# psc3 register map
Vendor: Infineon Technologies; Series: PSC3; File version: 1.0
CPU: CM33 r0p1, little endian, MPU, FPU, VTOR, 3 interrupt priority bits
Registers are 32-bit, read-write, reset 0x0 unless marked. A register's access mark holds for its fields unless they carry their own. Offsets are from the block's base; [hi:lo] are bit positions; lines under a group give offsets from that group; {n}, {i} and the like mark numbered series.

## MXCORDIC_1_0
Base 0x42240000
0x00 CTL
  [31] ENABLED — Enables/Disables IP
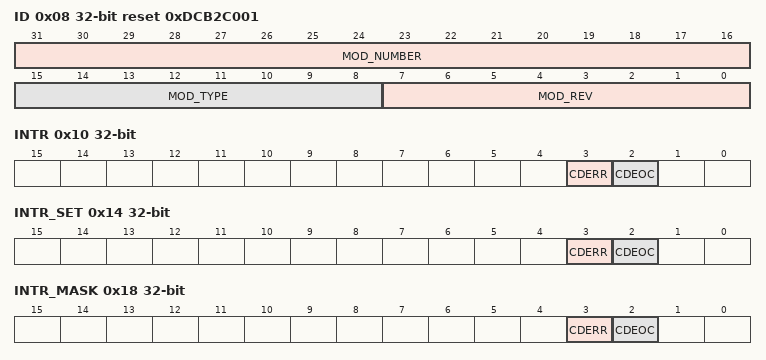
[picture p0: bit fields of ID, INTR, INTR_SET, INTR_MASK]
0x08 ID ro reset 0xDCB2C001 — Module Identification Register
  [31:16] MOD_NUMBER — Module Number Value - MOD_NUMBER
  [15:8] MOD_TYPE — Module Type - MOD_TYPE
  [7:0] MOD_REV — Module Revision Number - MOD_REV
0x10 INTR — Interrupt Cause Register
  [3] CDERR — CORDIC Error Event Flag - CDERR
  [2] CDEOC — CORDIC End of Calculation Event Flag - CDEOC
0x14 INTR_SET — Interrupt Set Register
  [3] CDERR — CORDIC Error Event Flag Set - CDERR
  [2] CDEOC — CORDIC Event Flag Set - CDEOC
0x18 INTR_MASK — Interrupt Mask Register
  [3] CDERR — CORDIC Error Interrupt Mask - CDERR
  [2] CDEOC — CORDIC End of Calculation Interrupt Mask- CDEOC
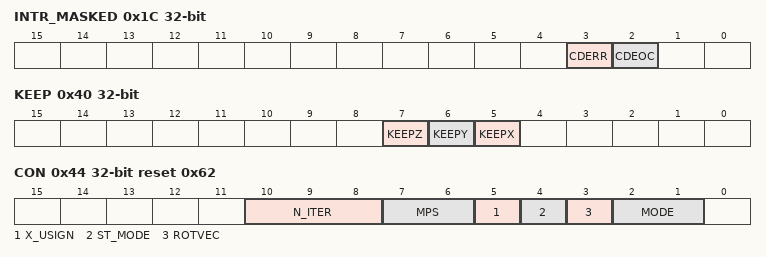
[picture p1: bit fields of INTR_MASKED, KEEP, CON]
0x1C INTR_MASKED ro — Interrupt Masked Register
  [3] CDERR — CORDIC Error Interrupt Masked - CDERR
  [2] CDEOC — CORDIC End of Calculation Interrupt Masked- CDEOC
0x40 KEEP — CORDIC Keep Register
  [7] KEEPZ — Last Z Result as Initial Data for New Calculation - KEEPZ
  [6] KEEPY — Last Y Result as Initial Data for New Calculation - KEEPY
  [5] KEEPX — Last X Result as Initial Data for New Calculation - KEEPX
0x44 CON reset 0x62 — CORDIC Control Register
  [10:8] N_ITER — Number of CORDIC iterations divided by 4
    {v}=N/A (v=1..7)
  [7:6] MPS — X and Y Magnitude Prescaler - MPS
    0=DIVIDE_BY_1 (N/A); 1=DIVIDE_BY_2 (N/A); 2=DIVIDE_BY_4 (N/A); 3=NO_CHANGE (N/A)
  [5] X_USIGN — Result Data Format for X in Circular Vectoring Mode - X_USIGN
    0=SIGNED (N/A); 1=UNSIGNED (N/A)
  [4] ST_MODE — Start Method - ST_MODE
    0=AUTO (Operation starts with write into CORDZ register); 1=ST (Operation starts with write into START_CMD register)
  [3] ROTVEC — Rotation Vectoring Selection - ROTVEC
    0=VECTORING (N/A); 1=ROTATION (N/A)
  [2:1] MODE — Operating Mode - MODE
    0=LINEAR (N/A); 1=CIRCULAR (N/A); 2=RSVD (N/A); 3=HYPERBOLIC (N/A)
0x48 CORDX — CORDIC X Data Register
  [31:8] DATA — Initial X Parameter Data - DATA
0x4C CORDY — CORDIC Y Data Register
  [31:8] DATA — Initial Y Parameter Data - DATA
0x50 CORDZ — CORDIC Z Data Register
  [31:8] DATA — Initial Z Parameter Data - DATA
0x54 CORRX ro — CORDIC X Result Register
  [31:8] RESULT — X Calculation Result - RESULT
0x58 CORRY ro — CORDIC Y Result Register
  [31:8] RESULT — Y Calculation Result - RESULT
0x5C CORRZ ro — CORDIC Z Result Register
  [31:8] RESULT — Z Calculation Result - RESULT
0x60 STAT ro — CORDIC Status Register
  [0] BSY — Busy Indication - BSY
0x64 START_CMD — CORDIC Start Command Register
  [0] ST — Start Calculation Set - ST

## DEBUG600
Base 0x42250000
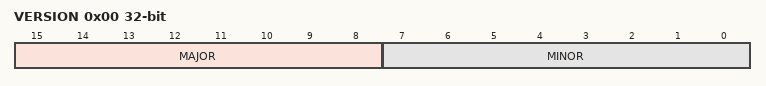
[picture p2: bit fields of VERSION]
0x00 VERSION ro reset not defined — IP Version Information
  [15:8] MAJOR — IP Major Revision Number
  [7:0] MINOR — IP Minor Revision Number

## HSIOM — IO Matrix (IOM)
Base 0x42400000
{0x0+0x10*i} PRT[{i}] (i=0..9) group — HSIOM port registers
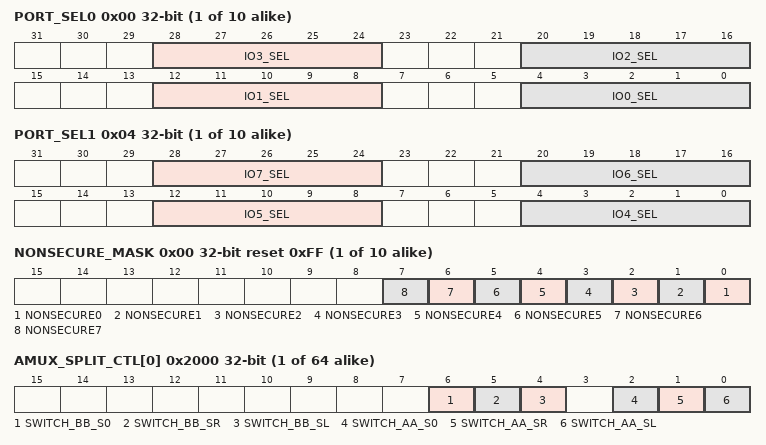
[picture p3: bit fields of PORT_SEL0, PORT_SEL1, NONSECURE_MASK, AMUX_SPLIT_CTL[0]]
  0x00 PORT_SEL0 — Port selection 0
    [28:24] IO3_SEL — Selects connection for IO pin 3 route.
    [20:16] IO2_SEL — Selects connection for IO pin 2 route.
    [12:8] IO1_SEL — Selects connection for IO pin 1 route.
    [4:0] IO0_SEL — Selects connection for IO pin 0 route.
      0=GPIO (GPIO controls 'out'); 1=GPIO_DSI (GPIO controls 'out', DSI controls 'output enable'); 2=DSI_DSI (DSI controls 'out' and 'output enable'); 3=DSI_GPIO (DSI controls 'out', GPIO controls 'output enable'); 4=AMUXA (Analog mux bus A); 5=AMUXB (Analog mux bus B); 6=AMUXA_DSI (Analog mux bus A, DSI control); 7=AMUXB_DSI (Analog mux bus B, DSI control); {v}=ACT_{v-8} (Active functionality {v-8}) (v=8..11); {v}=DS_{v-12} (DeepSleep functionality {v-12}) (v=12..15); {v}=ACT_{v-12} (Active functionality {v-12}) (v=16..27); {v}=DS_{v-24} (DeepSleep functionality {v-24}) (v=28..31)
  0x04 PORT_SEL1 — Port selection 1
    [28:24] IO7_SEL — Selects connection for IO pin 7 route.
    [20:16] IO6_SEL — Selects connection for IO pin 6 route.
    [12:8] IO5_SEL — Selects connection for IO pin 5 route.
    [4:0] IO4_SEL — Selects connection for IO pin 4 route. See PORT_SEL0 for connection details.
{0x1000+0x10*i} SECURE_PRT[{i}] (i=0..9) group — HSIOM secure attribute port registers
  0x00 NONSECURE_MASK reset 0xFF
    [n] NONSECURE{n} (n=0..7) — Non-secure attribute for IO{n}. 0 - Allows Secure access only. 1 - Allows Non-secure access only.
{0x2000+4i} AMUX_SPLIT_CTL[{i}] (i=0..63) — AMUX splitter cell control
  [6] SWITCH_BB_S0 — T-switch control for AMUXBUSB vssa/ground switch.
  [5] SWITCH_BB_SR — T-switch control for Right AMUXBUSB switch.
  [4] SWITCH_BB_SL — T-switch control for Left AMUXBUSB switch.
  [2] SWITCH_AA_S0 — T-switch control for AMUXBUSA vssa/ground switch: '0': switch open. '1': switch closed.
  [1] SWITCH_AA_SR — T-switch control for Right AMUXBUSA switch: '0': switch open. '1': switch closed.
  [0] SWITCH_AA_SL — T-switch control for Left AMUXBUSA switch: '0': switch open. '1': switch closed.
{0x2200+4i} MONITOR_CTL_{i} (i=0..3) — Power/Ground Monitor cell control {i}
  [31:0] MONITOR_EN — control for switch, which connects the power/ground supply to AMUXBUS_A/B respectively when switch is closed: '0': switch open. '1': switch closed.

## CANFD0 (part 1 of 3) — CAN Controller
Base 0x42800000
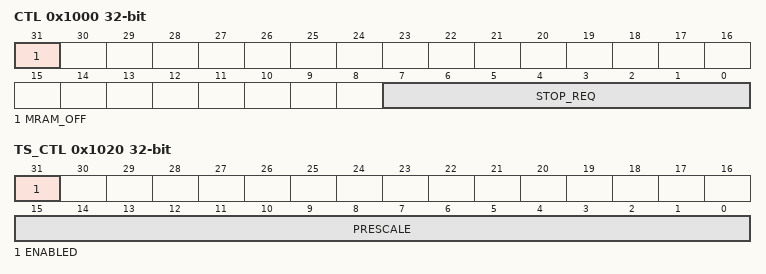
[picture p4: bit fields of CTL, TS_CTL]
0x1000 CTL — Global CAN control register
  [31] MRAM_OFF — MRAM off 0= Default MRAM on (with MRAM retained in DeepSleep). 1= Switch MRAM off (not retained) to save power. Before setting this bit all the CAN channels have to be powered down using the STOP_REQ/ACK bits. When the MRAM is off any access attempt to it is considered an address error (as if MRAM_SIZE=0). After switching the MRAM on again software needs to allow for a certain power up time before MRAM can be used, i.e. before STOP_REQ can be de-asserted. The power up time is equivalent to the system SRAM power up time specified in the CPUSS.RAM_PWR_DELAY_CTL register.
  [7:0] STOP_REQ
0x1004 STATUS ro — Global CAN status register
  [7:0] STOP_ACK — Clock Stop Acknowledge for each TTCAN IP. These bits are directly driven by m_ttcan_clkstop_ack of each TTCAN IP. When this bit is set the corresponding TTCAN IP clocks will be gated off, except HCLK will enabled for each AHB write
0x1010 INTR0_CAUSE ro — Consolidated interrupt0 cause register
  [7:0] INT0 — Show pending m_ttcan_int0 of each channel
0x1014 INTR1_CAUSE ro — Consolidated interrupt1 cause register
  [7:0] INT1 — Show pending m_ttcan_int1 of each channel
0x1020 TS_CTL — Time Stamp control register
  [31] ENABLED — Counter enable bit 0 = Count disabled. Stop counting up and keep the counter value 1 = Count enabled. Start counting up from the current value
  [15:0] PRESCALE — Time Stamp counter prescale value. When enabled divide the Host clock (HCLK) by PRESCALE+1 to create Time Stamp clock ticks.
0x1024 TS_CNT — Time Stamp counter value
  [15:0] VALUE — The counter value of the Time Stamp Counter. When enabled this counter will count Time Stamp clock ticks from the pre-scaler. When written this counter and the pre-scaler will reset to 0 (write data is ignored).
